# ESP32-C61 register map
Vendor: ESPRESSIF SYSTEMS (SHANGHAI) CO., LTD.; Series: ESP32 C-Series; File version: 1
CPU: RV32IMAC r0p0, little endian, no MPU, no FPU, 0 interrupt priority bits
Address unit: 32 bits
Registers are 32-bit, read-write, reset 0x0 unless marked. A register's access mark holds for its fields unless they carry their own. Offsets are from the block's base; [hi:lo] are bit positions; {n}, {i} and the like mark numbered series.

## MODEM_LPCON
Base 0x600AF000
0x00 TEST_CONF
  [0] CLK_EN
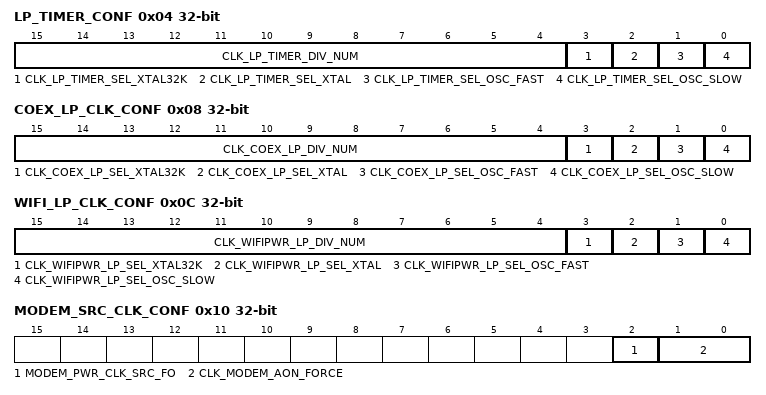
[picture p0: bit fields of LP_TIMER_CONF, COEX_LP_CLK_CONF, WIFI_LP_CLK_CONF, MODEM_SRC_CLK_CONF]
0x04 LP_TIMER_CONF
  [15:4] CLK_LP_TIMER_DIV_NUM, [3] CLK_LP_TIMER_SEL_XTAL32K, [2] CLK_LP_TIMER_SEL_XTAL, [1] CLK_LP_TIMER_SEL_OSC_FAST, [0] CLK_LP_TIMER_SEL_OSC_SLOW
0x08 COEX_LP_CLK_CONF
  [15:4] CLK_COEX_LP_DIV_NUM, [3] CLK_COEX_LP_SEL_XTAL32K, [2] CLK_COEX_LP_SEL_XTAL, [1] CLK_COEX_LP_SEL_OSC_FAST, [0] CLK_COEX_LP_SEL_OSC_SLOW
0x0C WIFI_LP_CLK_CONF
  [15:4] CLK_WIFIPWR_LP_DIV_NUM, [3] CLK_WIFIPWR_LP_SEL_XTAL32K, [2] CLK_WIFIPWR_LP_SEL_XTAL, [1] CLK_WIFIPWR_LP_SEL_OSC_FAST, [0] CLK_WIFIPWR_LP_SEL_OSC_SLOW
0x10 MODEM_SRC_CLK_CONF
  [2] MODEM_PWR_CLK_SRC_FO, [1:0] CLK_MODEM_AON_FORCE
0x14 MODEM_32K_CLK_CONF
  [1:0] CLK_MODEM_32K_SEL
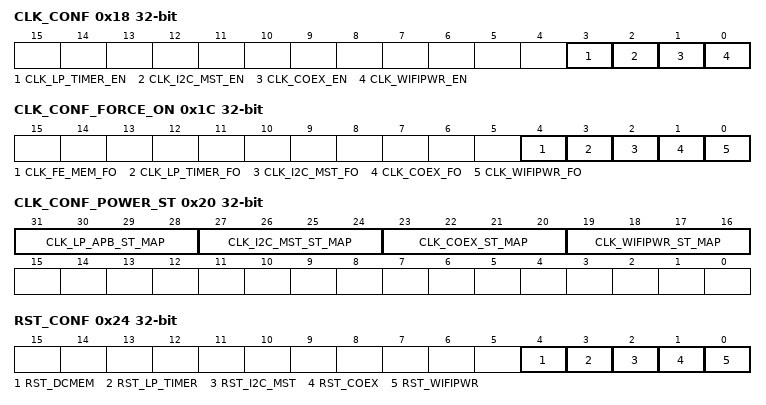
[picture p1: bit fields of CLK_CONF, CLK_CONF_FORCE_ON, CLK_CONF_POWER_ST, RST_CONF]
0x18 CLK_CONF
  [3] CLK_LP_TIMER_EN, [2] CLK_I2C_MST_EN, [1] CLK_COEX_EN, [0] CLK_WIFIPWR_EN
0x1C CLK_CONF_FORCE_ON
  [4] CLK_FE_MEM_FO, [3] CLK_LP_TIMER_FO, [2] CLK_I2C_MST_FO, [1] CLK_COEX_FO, [0] CLK_WIFIPWR_FO
0x20 CLK_CONF_POWER_ST
  [31:28] CLK_LP_APB_ST_MAP, [27:24] CLK_I2C_MST_ST_MAP, [23:20] CLK_COEX_ST_MAP, [19:16] CLK_WIFIPWR_ST_MAP
0x24 RST_CONF wo
  [4] RST_DCMEM, [3] RST_LP_TIMER, [2] RST_I2C_MST, [1] RST_COEX, [0] RST_WIFIPWR
0x28 TICK_CONF reset 0x27
  [5:0] MODEM_PWR_TICK_TARGET
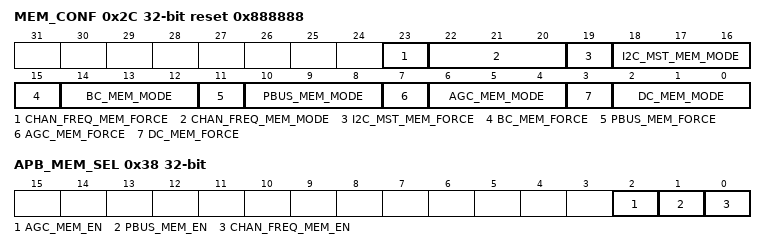
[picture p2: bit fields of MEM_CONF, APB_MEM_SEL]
0x2C MEM_CONF reset 0x888888
  [23] CHAN_FREQ_MEM_FORCE, [22:20] CHAN_FREQ_MEM_MODE, [19] I2C_MST_MEM_FORCE, [18:16] I2C_MST_MEM_MODE, [15] BC_MEM_FORCE, [14:12] BC_MEM_MODE, [11] PBUS_MEM_FORCE, [10:8] PBUS_MEM_MODE, [7] AGC_MEM_FORCE, [6:4] AGC_MEM_MODE, [3] DC_MEM_FORCE, [2:0] DC_MEM_MODE
0x30 MEM_RF1_AUX_CTRL reset 0x2070
  [31:0] MODEM_PWR_RF1_AUX_CTRL
0x34 MEM_RF2_AUX_CTRL
  [31:0] MODEM_PWR_RF2_AUX_CTRL
0x38 APB_MEM_SEL
  [2] AGC_MEM_EN, [1] PBUS_MEM_EN, [0] CHAN_FREQ_MEM_EN
{0x3C+4i} DCMEM_VALID_{i} ro (i=0..3)
0x4C DATE

## I2C_ANA_MST — I2C_ANA_MST Peripheral
Base 0x600AF800
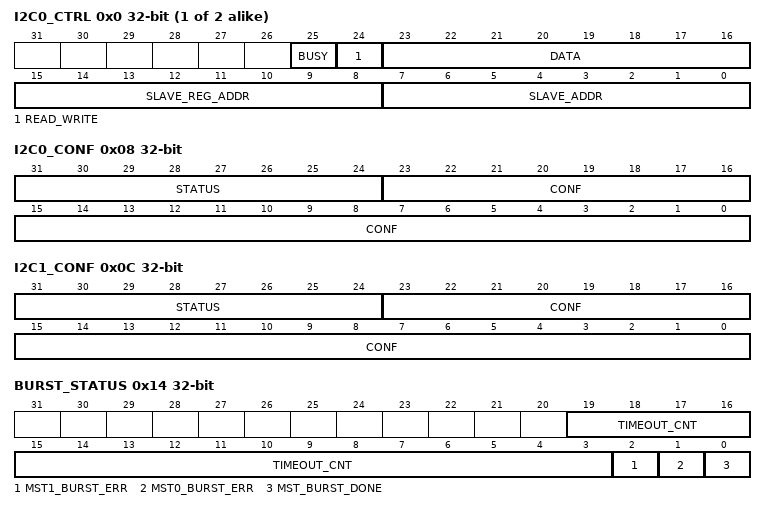
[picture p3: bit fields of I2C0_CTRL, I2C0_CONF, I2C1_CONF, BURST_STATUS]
{0x0+4i} I2C{i}_CTRL (i=0..1) — I2C{i}_CTRL register
  [25] BUSY ro — Represents whether I2C0 is currently transferring data
  [24] READ_WRITE — Configures the read/write operation
  [23:16] DATA — Configures the transmitted data
  [15:8] SLAVE_REG_ADDR — Configures the slave register address
  [7:0] SLAVE_ADDR — Configures the slave address
0x08 I2C0_CONF
  [31:24] STATUS ro — ?
  [23:0] CONF — ?
0x0C I2C1_CONF
  [31:24] STATUS ro — ?
  [23:0] CONF — ?
0x10 BURST_CONF
  [31:0] BURST_CTRL — ?
0x14 BURST_STATUS
  [19:3] TIMEOUT_CNT ro — ?
  [2] MST1_BURST_ERR ro — ?
  [1] MST0_BURST_ERR ro — ?
  [0] MST_BURST_DONE ro — ?
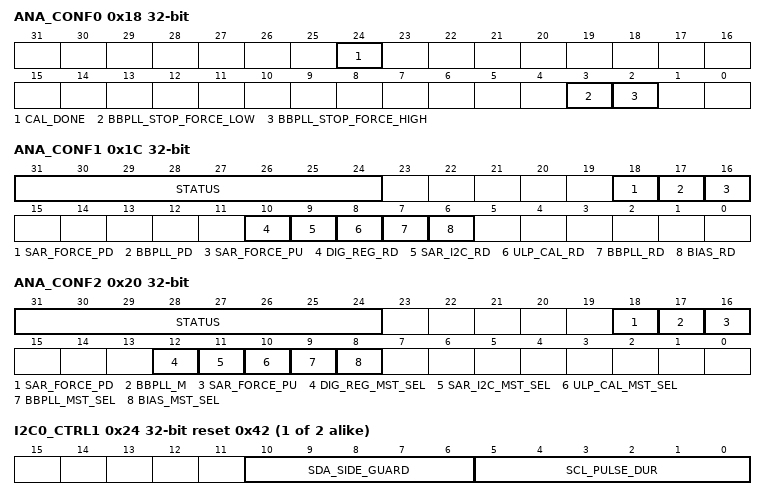
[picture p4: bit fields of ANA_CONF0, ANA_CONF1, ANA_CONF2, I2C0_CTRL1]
0x18 ANA_CONF0
  [24] CAL_DONE ro — BBPLL calibration done
  [3] BBPLL_STOP_FORCE_LOW — ?
  [2] BBPLL_STOP_FORCE_HIGH — ?
0x1C ANA_CONF1
  [31:24] STATUS ro — ?
  [18] SAR_FORCE_PD — ?
  [17] BBPLL_PD — Clear to enable BBPLL
  [16] SAR_FORCE_PU — ?
  [10] DIG_REG_RD — Clear to select
  [9] SAR_I2C_RD — Clear to select
  [8] ULP_CAL_RD — Clear to select
  [7] BBPLL_RD — Clear to select
  [6] BIAS_RD — Clear to select
0x20 ANA_CONF2
  [31:24] STATUS ro — ?
  [18] SAR_FORCE_PD — ?
  [17] BBPLL_M — Clear to enable BBPLL
  [16] SAR_FORCE_PU — ?
  [12] DIG_REG_MST_SEL — Configures which I2C master the following analog modules uses. If the corresponding bit is set to 1, I2C0 master is used for communication; if set to 0, I2C1 master is used.
  [11] SAR_I2C_MST_SEL — Configures which I2C master the following analog modules uses. If the corresponding bit is set to 1, I2C0 master is used for communication; if set to 0, I2C1 master is used.
  [10] ULP_CAL_MST_SEL — Configures which I2C master the following analog modules uses. If the corresponding bit is set to 1, I2C0 master is used for communication; if set to 0, I2C1 master is used.
  [9] BBPLL_MST_SEL — Configures which I2C master the following analog modules uses. If the corresponding bit is set to 1, I2C0 master is used for communication; if set to 0, I2C1 master is used.
  [8] BIAS_MST_SEL — Configures which I2C master the following analog modules uses. If the corresponding bit is set to 1, I2C0 master is used for communication; if set to 0, I2C1 master is used.
{0x24+4i} I2C{i}_CTRL1 (i=0..1) reset 0x42 — I2C{i}_CTRL1 register
  [10:6] SDA_SIDE_GUARD — Configures the duration of the low-level period of the SCL driven by I2C0
  [5:0] SCL_PULSE_DUR — Configures the duration of the high-level period of the SCL driven by I2C0
0x34 DATE
